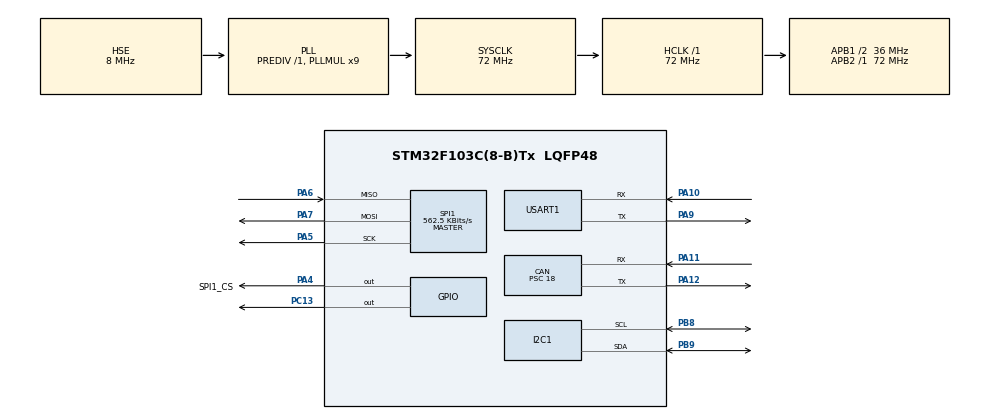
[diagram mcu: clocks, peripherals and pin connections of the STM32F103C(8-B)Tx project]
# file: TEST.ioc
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CAN.ABOM=ENABLE
CAN.AWUM=ENABLE
CAN.BS1=CAN_BS1_7TQ
CAN.BS2=CAN_BS2_2TQ
CAN.CalculateBaudRate=200000
CAN.CalculateTimeBit=5000
CAN.CalculateTimeQuantum=500.0
CAN.Mode=CAN_MODE_NORMAL
CAN.NART=ENABLE
CAN.Prescaler=18
CAN.SJW=CAN_SJW_2TQ
Mcu.Family=STM32F1
Mcu.Name=STM32F103C(8-B)Tx
Mcu.Package=LQFP48
NVIC.CAN1_RX1_IRQn=true\:4\:0\:true\:false\:true\:true\:true\:true
NVIC.PriorityGroup=NVIC_PRIORITYGROUP_4
NVIC.USART1_IRQn=true\:5\:0\:true\:false\:true\:true\:true\:true
PA10.Mode=Asynchronous
PA10.Signal=USART1_RX
PA11.Mode=CAN_Activate
PA11.Signal=CAN_RX
PA12.Mode=CAN_Activate
PA12.Signal=CAN_TX
PA13.Mode=Serial_Wire
PA13.Signal=SYS_JTMS-SWDIO
PA14.Mode=Serial_Wire
PA14.Signal=SYS_JTCK-SWCLK
PA4.GPIO_Label=SPI1_CS
PA4.GPIO_PuPd=GPIO_PULLUP
PA4.GPIO_Speed=GPIO_SPEED_FREQ_HIGH
PA4.PinState=GPIO_PIN_SET
PA4.Signal=GPIO_Output
PA5.Mode=Full_Duplex_Master
PA5.Signal=SPI1_SCK
PA6.Mode=Full_Duplex_Master
PA6.Signal=SPI1_MISO
PA7.Mode=Full_Duplex_Master
PA7.Signal=SPI1_MOSI
PA9.Mode=Asynchronous
PA9.Signal=USART1_TX
PB8.Mode=I2C
PB8.Signal=I2C1_SCL
PB9.Mode=I2C
PB9.Signal=I2C1_SDA
PC13-TAMPER-RTC.GPIO_ModeDefaultOutputPP=GPIO_MODE_OUTPUT_OD
PC13-TAMPER-RTC.GPIO_PuPd=GPIO_NOPULL
PC13-TAMPER-RTC.PinState=GPIO_PIN_SET
PC13-TAMPER-RTC.Signal=GPIO_Output
PC14-OSC32_IN.Mode=LSE-External-Oscillator
PC14-OSC32_IN.Signal=RCC_OSC32_IN
PC15-OSC32_OUT.Mode=LSE-External-Oscillator
PC15-OSC32_OUT.Signal=RCC_OSC32_OUT
PD0-OSC_IN.Mode=HSE-External-Oscillator
PD0-OSC_IN.Signal=RCC_OSC_IN
PD1-OSC_OUT.Mode=HSE-External-Oscillator
PD1-OSC_OUT.Signal=RCC_OSC_OUT
ProjectManager.HeapSize=0x200
ProjectManager.StackSize=0x400
ProjectManager.TargetToolchain=CMake
RCC.AHBFreq_Value=72000000
RCC.APB1CLKDivider=RCC_HCLK_DIV2
RCC.APB1Freq_Value=36000000
RCC.APB1TimFreq_Value=72000000
RCC.APB2Freq_Value=72000000
RCC.APB2TimFreq_Value=72000000
RCC.HCLKFreq_Value=72000000
RCC.PLLMUL=RCC_PLL_MUL9
RCC.PLLSourceVirtual=RCC_PLLSOURCE_HSE
RCC.SYSCLKFreq_VALUE=72000000
RCC.SYSCLKSource=RCC_SYSCLKSOURCE_PLLCLK
RCC.USBFreq_Value=72000000
SPI1.BaudRatePrescaler=SPI_BAUDRATEPRESCALER_128
SPI1.CalculateBaudRate=562.5 KBits/s
SPI1.Direction=SPI_DIRECTION_2LINES
SPI1.Mode=SPI_MODE_MASTER
SPI1.VirtualType=VM_MASTER
USART1.Parity=PARITY_NONE
USART1.VirtualMode=VM_ASYNC
board=custom

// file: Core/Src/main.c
/* USER CODE BEGIN Header */
/**
  ******************************************************************************
  * @file           : main.c
  * @brief          : Main program body
  ******************************************************************************
  * @attention
  *
  * Copyright (c) 2026 STMicroelectronics.
  * All rights reserved.
  *
  * This software is licensed under terms that can be found in the LICENSE file
  * in the root directory of this software component.
  * If no LICENSE file comes with this software, it is provided AS-IS.
  *
  ******************************************************************************
  */
/* USER CODE END Header */
#include "main.h"
#include "can.h"
#include "i2c.h"
#include "spi.h"
#include "usart.h"
#include "gpio.h"

/* USER CODE BEGIN Includes */
#include "app_update.h"
#include "Int_can.h"
#include "int_w25q64.h"
#include "int_at24c02.h"
/* USER CODE END Includes */

/* USER CODE BEGIN PD */
#define APP_START_ADDR 0x8005000
/* USER CODE END PD */

/* USER CODE BEGIN PV */
// CAN_TxHeaderTypeDef TxHeader1={
//   .StdId = 0x123,.ExtId = 0x00000000, .IDE = CAN_ID_STD, .RTR = CAN_RTR_DATA,
//   .DLC =5, .TransmitGlobalTime = DISABLE,
// };
//
// CAN_TxHeaderTypeDef TxHeader2={
//   .StdId = 0x000,.ExtId = 0x00000000, .IDE = CAN_ID_STD, .RTR = CAN_RTR_DATA,
//   .DLC =4, .TransmitGlobalTime = DISABLE,
// };
// uint8_t CMD[4] = {0xAA,0xBB,0xAA,0xBB};
//
// CAN_Msg_t RxMsg;

/* USER CODE END PV */

void SystemClock_Config(void);

int main(void)
{

  /* USER CODE BEGIN 1 */

  // RCC->APB2ENR |= RCC_APB2ENR_IOPCEN;   // 使能 GPIOC 时钟
  // GPIOC->CRH &= ~(0xF << 20);            // 清除 PC13 配置
  // GPIOC->CRH |= (0x3 << 20);             // PC13 推挽输出，50MHz
  // GPIOC->BRR = GPIO_PIN_13;              // 点亮（低电平）

  //重定向中断向量表
  __disable_irq();
  SCB->VTOR = APP_START_ADDR;
  __enable_irq();

  /* 翻转1表示VTOR完了 */
  // GPIOC->BSRR = GPIO_PIN_13;
  // for(volatile int i=0;i<500000;i++);
  // GPIOC->BRR = GPIO_PIN_13;
  // //
  //  while(1);  // 死循环，看灯亮不亮

  /* USER CODE END 1 */

  /* MCU Configuration--------------------------------------------------------*/

  /* Reset of all peripherals, Initializes the Flash interface and the Systick. */
   HAL_Init();

  /* USER CODE BEGIN Init */
  /* 翻转1表示VTOR完了 */
  // GPIOC->BSRR = GPIO_PIN_13;
  // for(volatile int i=0;i<500000;i++);
  // GPIOC->BRR = GPIO_PIN_13;
  /* USER CODE END Init */

  /* Configure the system clock */
   SystemClock_Config();

  /* USER CODE BEGIN SysInit */
  // GPIOC->BSRR = GPIO_PIN_13;
  // while(1);
  /* USER CODE END SysInit */

  /* Initialize all configured peripherals */
  MX_GPIO_Init();
  MX_USART1_UART_Init();
  MX_CAN_Init();
  MX_SPI1_Init();
  MX_I2C1_Init();
  /* USER CODE BEGIN 2 */

   App_Update_Init();

  // uint8_t mf_id;
  // uint16_t chip_id;
  // Int_W25Q64_Read_ID(&mf_id, &chip_id);
  // printf("JEDEC: mf=%02X id=%04X\r\n", mf_id, chip_id);
  // printf("APP started\r\n");

  /* USER CODE END 2 */

  /* Infinite loop */
  /* USER CODE BEGIN WHILE */
  // HAL_GPIO_TogglePin(GPIOC, GPIO_PIN_13);
  while (1)
  {
    App_Update_Work();
    // HAL_GPIO_TogglePin(GPIOC, GPIO_PIN_13);
    // HAL_Delay(500);
    /* USER CODE END WHILE */

  }
}

void SystemClock_Config(void)
{
  //
  //HAL_RCC_DeInit();  // ← 加在这里，把时钟复位到复位默认状态（HSI）
  //

  RCC_OscInitTypeDef RCC_OscInitStruct = {0};
  RCC_ClkInitTypeDef RCC_ClkInitStruct = {0};

  /** Initializes the RCC Oscillators according to the specified parameters
  * in the RCC_OscInitTypeDef structure.
  */
  RCC_OscInitStruct.OscillatorType = RCC_OSCILLATORTYPE_HSE;
  RCC_OscInitStruct.HSEState = RCC_HSE_ON;
  RCC_OscInitStruct.HSEPredivValue = RCC_HSE_PREDIV_DIV1;
  RCC_OscInitStruct.HSIState = RCC_HSI_ON;
  RCC_OscInitStruct.PLL.PLLState = RCC_PLL_ON;
  RCC_OscInitStruct.PLL.PLLSource = RCC_PLLSOURCE_HSE;
  RCC_OscInitStruct.PLL.PLLMUL = RCC_PLL_MUL9;
  if (HAL_RCC_OscConfig(&RCC_OscInitStruct) != HAL_OK)
  {
    Error_Handler();
  }

  /** Initializes the CPU, AHB and APB buses clocks
  */
  RCC_ClkInitStruct.ClockType = RCC_CLOCKTYPE_HCLK|RCC_CLOCKTYPE_SYSCLK
                              |RCC_CLOCKTYPE_PCLK1|RCC_CLOCKTYPE_PCLK2;
  RCC_ClkInitStruct.SYSCLKSource = RCC_SYSCLKSOURCE_PLLCLK;
  RCC_ClkInitStruct.AHBCLKDivider = RCC_SYSCLK_DIV1;
  RCC_ClkInitStruct.APB1CLKDivider = RCC_HCLK_DIV2;
  RCC_ClkInitStruct.APB2CLKDivider = RCC_HCLK_DIV1;

  if (HAL_RCC_ClockConfig(&RCC_ClkInitStruct, FLASH_LATENCY_2) != HAL_OK)
  {
    Error_Handler();
  }
}

void Error_Handler(void)
{
  __disable_irq();
  while (1)
  {
  }
}
